AUTOSAR XML (schema 4-1-2)
package /MICROSAR_SWCS_DEV/IoHwAb_swc/ComponentTypes
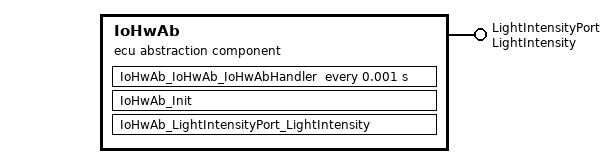
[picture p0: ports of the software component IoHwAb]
  ecu abstraction sw component type IoHwAb
    provide port LightIntensityPort: server-com-spec{operation=LightIntensity, queue-length=1}, provided-interface=LightIntensity
    behavior IoHwAbInternalBehavior
      init event IoHwAb_InitEvent: start-on-event=IoHwAb_Init
      timing event Timer_IoHwAb_IoHwAb_IoHwAbHandler: start-on-event=IoHwAb_IoHwAb_IoHwAbHandler, period=0.001
      operation invoked event OIT_IoHwAb_LightIntensityPort_LightIntensity_LightIntensityPort_LightIntensity: start-on-event=IoHwAb_LightIntensityPort_LightIntensity, operation=LightIntensityPort.LightIntensity
      runnable IoHwAb_Init
      runnable IoHwAb_IoHwAb_IoHwAbHandler: can-be-invoked-concurrently=true
      runnable IoHwAb_LightIntensityPort_LightIntensity: can-be-invoked-concurrently=true  # Runnable Entity for calling the Operation 'LightIntensity' of the Client/Server Port Prototype 'LightIntensityPort'.
  swc implementation IoHwAbImplementation: behavior=IoHwAbInternalBehavior
    code-descriptors:
      code Default: artifact-descriptors=autosar-engineering-object={short-label=Default, category=SWSRC}
